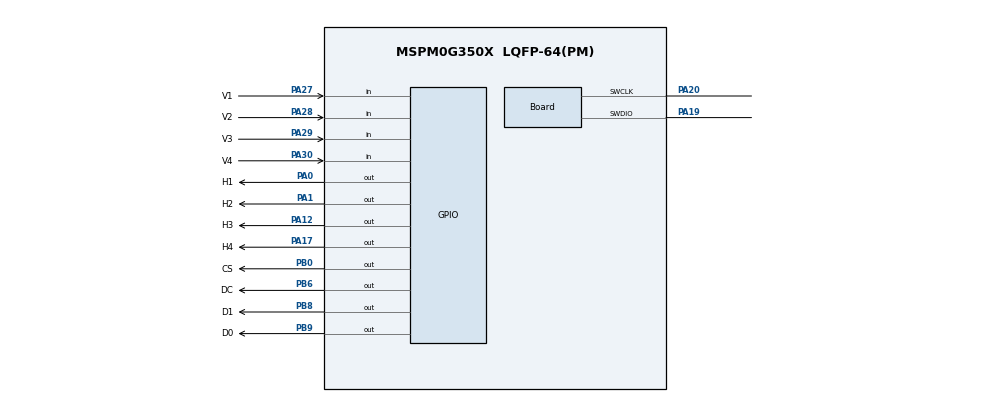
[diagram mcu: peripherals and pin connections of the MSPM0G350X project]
/**
 * @cliArgs --device "MSPM0G350X" --package "LQFP-64(PM)" --part "Default" --product "mspm0_sdk@1.20.01.06"
 * @versions {"tool":"1.18.1+3343"}
 */

/**
 * Import the modules used in this configuration.
 */
const Board         = scripting.addModule("/ti/driverlib/Board");
const GPIO          = scripting.addModule("/ti/driverlib/GPIO", {}, false);
const GPIO1         = GPIO.addInstance();
const GPIO2         = GPIO.addInstance();
const SYSCTL        = scripting.addModule("/ti/driverlib/SYSCTL");
const ProjectConfig = scripting.addModule("/ti/project_config/ProjectConfig");

/**
 * Write custom configuration values to the imported modules.
 */
const gate7  = system.clockTree["MFCLKGATE"];
gate7.enable = true;

const gate8  = system.clockTree["MFPCLKGATE"];
gate8.enable = true;

Board.peripheral.$assign          = "DEBUGSS";
Board.peripheral.swclkPin.$assign = "PA20";
Board.peripheral.swdioPin.$assign = "PA19";

GPIO1.$name                              = "KEY";
GPIO1.associatedPins.create(8);
GPIO1.associatedPins[0].$name            = "H1";
GPIO1.associatedPins[0].assignedPin      = "0";
GPIO1.associatedPins[0].internalResistor = "PULL_UP";
GPIO1.associatedPins[0].pin.$assign      = "PA0";
GPIO1.associatedPins[1].$name            = "H2";
GPIO1.associatedPins[1].assignedPin      = "1";
GPIO1.associatedPins[1].internalResistor = "PULL_UP";
GPIO1.associatedPins[1].pin.$assign      = "PA1";
GPIO1.associatedPins[2].$name            = "H3";
GPIO1.associatedPins[2].assignedPin      = "12";
GPIO1.associatedPins[2].pin.$assign      = "PA12";
GPIO1.associatedPins[3].$name            = "H4";
GPIO1.associatedPins[3].assignedPin      = "17";
GPIO1.associatedPins[3].pin.$assign      = "PA17";
GPIO1.associatedPins[4].$name            = "V1";
GPIO1.associatedPins[4].direction        = "INPUT";
GPIO1.associatedPins[4].assignedPin      = "27";
GPIO1.associatedPins[4].internalResistor = "PULL_UP";
GPIO1.associatedPins[4].pin.$assign      = "PA27";
GPIO1.associatedPins[5].$name            = "V2";
GPIO1.associatedPins[5].direction        = "INPUT";
GPIO1.associatedPins[5].assignedPin      = "28";
GPIO1.associatedPins[5].internalResistor = "PULL_UP";
GPIO1.associatedPins[5].pin.$assign      = "PA28";
GPIO1.associatedPins[6].$name            = "V3";
GPIO1.associatedPins[6].direction        = "INPUT";
GPIO1.associatedPins[6].assignedPin      = "29";
GPIO1.associatedPins[6].internalResistor = "PULL_UP";
GPIO1.associatedPins[6].pin.$assign      = "PA29";
GPIO1.associatedPins[7].$name            = "V4";
GPIO1.associatedPins[7].direction        = "INPUT";
GPIO1.associatedPins[7].assignedPin      = "30";
GPIO1.associatedPins[7].internalResistor = "PULL_UP";
GPIO1.associatedPins[7].pin.$assign      = "PA30";

GPIO2.$name                         = "GPIO_GRP_0";
GPIO2.associatedPins.create(4);
GPIO2.associatedPins[0].$name       = "CS";
GPIO2.associatedPins[0].assignedPin = "0";
GPIO2.associatedPins[0].pin.$assign = "PB0";
GPIO2.associatedPins[1].$name       = "DC";
GPIO2.associatedPins[1].assignedPin = "6";
GPIO2.associatedPins[1].pin.$assign = "PB6";
GPIO2.associatedPins[2].$name       = "D0";
GPIO2.associatedPins[2].assignedPin = "9";
GPIO2.associatedPins[2].pin.$assign = "PB9";
GPIO2.associatedPins[3].$name       = "D1";
GPIO2.associatedPins[3].assignedPin = "8";
GPIO2.associatedPins[3].pin.$assign = "PB8";

SYSCTL.MFCLKEn     = true;
SYSCTL.MFPCLKEn    = true;
SYSCTL.clockTreeEn = true;

ProjectConfig.deviceSpin = "MSPM0G3507";
